# STM32F479 register map
File version: 2.0
CPU: CM4 r0p1, little endian, MPU, FPU, 4 interrupt priority bits
Registers are 32-bit, read-write, reset 0x0 unless marked. A register's access mark holds for its fields unless they carry their own. Offsets are from the block's base; [hi:lo] are bit positions; {n}, {i} and the like mark numbered series.

## EXTI — External interrupt/event controller
Base 0x40013C00
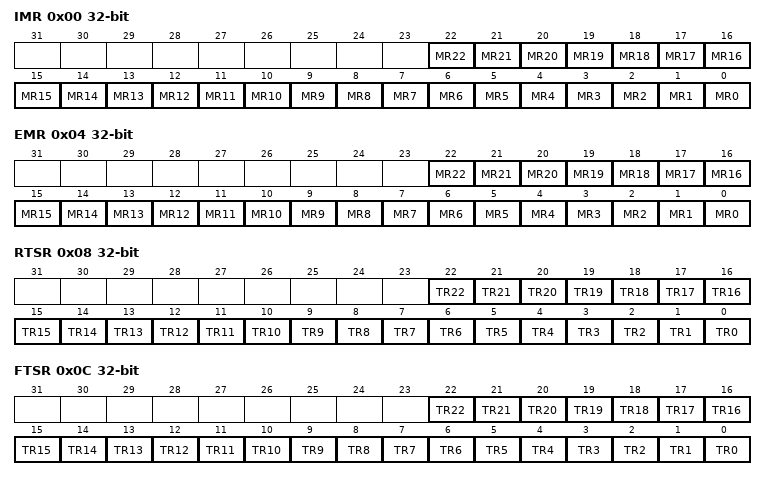
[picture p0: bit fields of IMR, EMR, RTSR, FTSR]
0x00 IMR — Interrupt mask register (EXTI_IMR)
  [n] MR{n} (n=0..22) — Interrupt Mask on line {n}
0x04 EMR — Event mask register (EXTI_EMR)
  [n] MR{n} (n=0..22) — Event Mask on line {n}
0x08 RTSR — Rising Trigger selection register (EXTI_RTSR)
  [n] TR{n} (n=0..22) — Rising trigger event configuration of line {n}
0x0C FTSR — Falling Trigger selection register (EXTI_FTSR)
  [n] TR{n} (n=0..22) — Falling trigger event configuration of line {n}
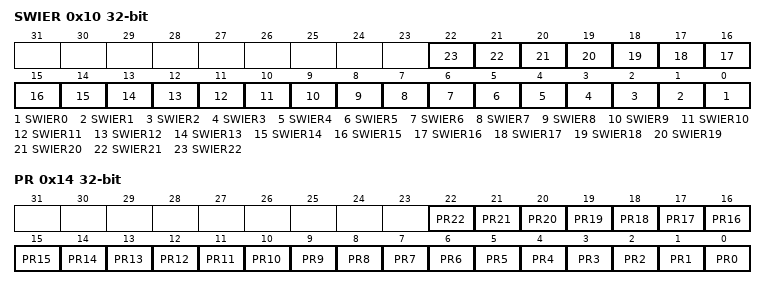
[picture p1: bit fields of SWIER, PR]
0x10 SWIER — Software interrupt event register (EXTI_SWIER)
  [n] SWIER{n} (n=0..22) — Software Interrupt on line {n}
0x14 PR — Pending register (EXTI_PR)
  [n] PR{n} (n=0..22) — Pending bit {n}

## Ethernet_DMA — Ethernet: DMA controller operation
Base 0x40029000
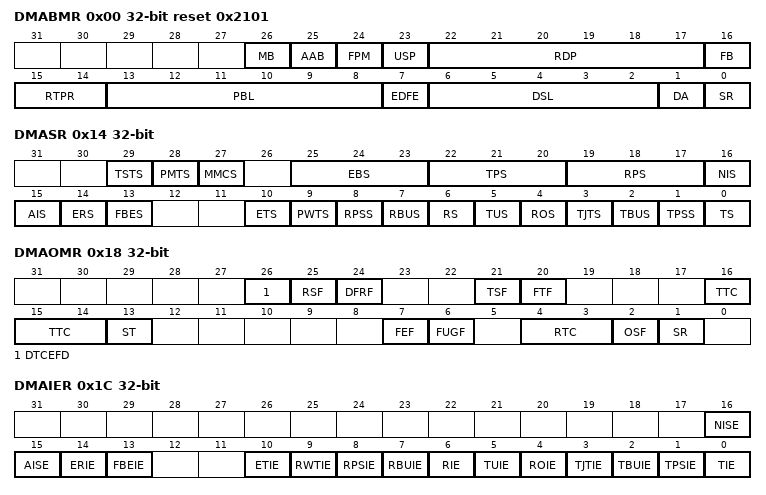
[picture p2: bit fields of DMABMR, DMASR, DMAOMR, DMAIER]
0x00 DMABMR reset 0x2101 — Ethernet DMA bus mode register
  [26] MB, [25] AAB, [24] FPM, [23] USP, [22:17] RDP, [16] FB, [15:14] RTPR, [13:8] PBL, [7] EDFE, [6:2] DSL, [1] DA, [0] SR
0x04 DMATPDR — Ethernet DMA transmit poll demand register
  [31:0] TPD
0x08 DMARPDR — EHERNET DMA receive poll demand register
  [31:0] RPD
0x0C DMARDLAR — Ethernet DMA receive descriptor list address register
  [31:0] SRL
0x10 DMATDLAR — Ethernet DMA transmit descriptor list address register
  [31:0] STL
0x14 DMASR access per field — Ethernet DMA status register
  [29] TSTS ro, [28] PMTS ro, [27] MMCS ro, [25:23] EBS ro, [22:20] TPS ro, [19:17] RPS ro, [16] NIS rw, [15] AIS rw, [14] ERS rw, [13] FBES rw, [10] ETS rw, [9] PWTS rw, [8] RPSS rw, [7] RBUS rw, [6] RS rw, [5] TUS rw, [4] ROS rw, [3] TJTS rw, [2] TBUS rw, [1] TPSS rw, [0] TS rw
0x18 DMAOMR — Ethernet DMA operation mode register
  [26] DTCEFD, [25] RSF, [24] DFRF, [21] TSF, [20] FTF, [16:14] TTC, [13] ST, [7] FEF, [6] FUGF, [4:3] RTC, [2] OSF, [1] SR
0x1C DMAIER — Ethernet DMA interrupt enable register
  [16] NISE, [15] AISE, [14] ERIE, [13] FBEIE, [10] ETIE, [9] RWTIE, [8] RPSIE, [7] RBUIE, [6] RIE, [5] TUIE, [4] ROIE, [3] TJTIE, [2] TBUIE, [1] TPSIE, [0] TIE
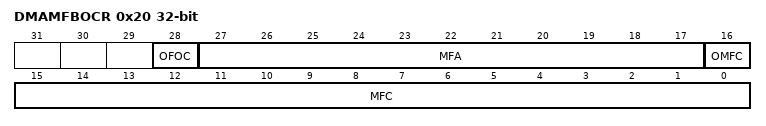
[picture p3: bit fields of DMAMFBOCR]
0x20 DMAMFBOCR — Ethernet DMA missed frame and buffer overflow counter register
  [28] OFOC, [27:17] MFA, [16] OMFC, [15:0] MFC
0x24 DMARSWTR — Ethernet DMA receive status watchdog timer register
  [7:0] RSWTC
0x48 DMACHTDR ro — Ethernet DMA current host transmit descriptor register
  [31:0] HTDAP
0x4C DMACHRDR ro — Ethernet DMA current host receive descriptor register
  [31:0] HRDAP
0x50 DMACHTBAR ro — Ethernet DMA current host transmit buffer address register
  [31:0] HTBAP
0x54 DMACHRBAR ro — Ethernet DMA current host receive buffer address register
  [31:0] HRBAP

## Ethernet_MAC — Ethernet: media access control (MAC)
Base 0x40028000
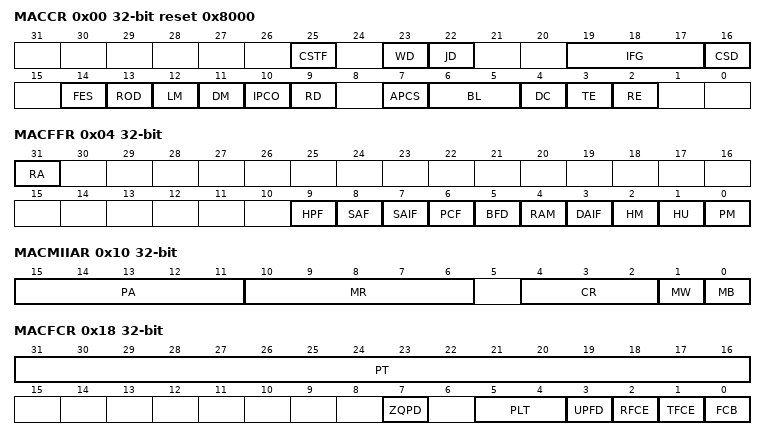
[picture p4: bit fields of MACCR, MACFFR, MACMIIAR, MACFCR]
0x00 MACCR reset 0x8000 — Ethernet MAC configuration register
  [25] CSTF, [23] WD, [22] JD, [19:17] IFG, [16] CSD, [14] FES, [13] ROD, [12] LM, [11] DM, [10] IPCO, [9] RD, [7] APCS, [6:5] BL, [4] DC, [3] TE, [2] RE
0x04 MACFFR — Ethernet MAC frame filter register
  [31] RA, [9] HPF, [8] SAF, [7] SAIF, [6] PCF, [5] BFD, [4] RAM, [3] DAIF, [2] HM, [1] HU, [0] PM
0x08 MACHTHR — Ethernet MAC hash table high register
  [31:0] HTH
0x0C MACHTLR — Ethernet MAC hash table low register
  [31:0] HTL
0x10 MACMIIAR — Ethernet MAC MII address register
  [15:11] PA, [10:6] MR, [4:2] CR, [1] MW, [0] MB
0x14 MACMIIDR — Ethernet MAC MII data register
  [15:0] TD
0x18 MACFCR — Ethernet MAC flow control register
  [31:16] PT, [7] ZQPD, [5:4] PLT, [3] UPFD, [2] RFCE, [1] TFCE, [0] FCB
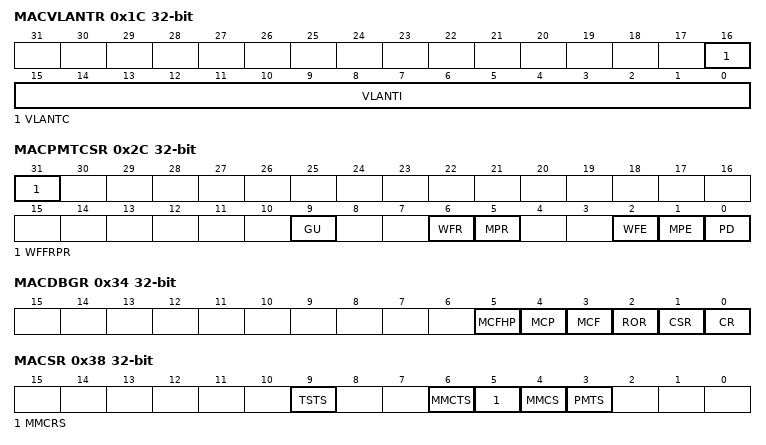
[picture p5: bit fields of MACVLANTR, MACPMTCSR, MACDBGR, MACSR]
0x1C MACVLANTR — Ethernet MAC VLAN tag register
  [16] VLANTC, [15:0] VLANTI
0x2C MACPMTCSR — Ethernet MAC PMT control and status register
  [31] WFFRPR, [9] GU, [6] WFR, [5] MPR, [2] WFE, [1] MPE, [0] PD
0x34 MACDBGR ro — Ethernet MAC debug register
  [5] MCFHP, [4] MCP, [3] MCF, [2] ROR, [1] CSR, [0] CR
0x38 MACSR access per field — Ethernet MAC interrupt status register
  [9] TSTS rw, [6] MMCTS ro, [5] MMCRS ro, [4] MMCS ro, [3] PMTS ro
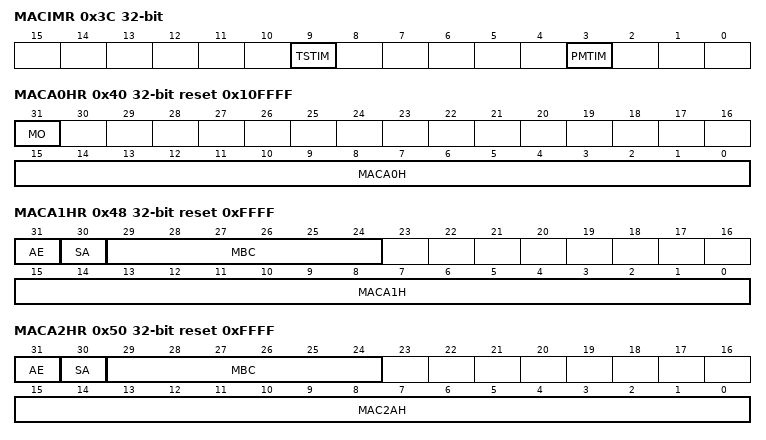
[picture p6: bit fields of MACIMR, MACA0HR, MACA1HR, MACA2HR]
0x3C MACIMR — Ethernet MAC interrupt mask register
  [9] TSTIM, [3] PMTIM
0x40 MACA0HR access per field reset 0x10FFFF — Ethernet MAC address 0 high register
  [31] MO ro — Always 1
  [15:0] MACA0H rw — MAC address0 high
0x44 MACA0LR reset 0xFFFFFFFF — Ethernet MAC address 0 low register
  [31:0] MACA0L — 0
0x48 MACA1HR reset 0xFFFF — Ethernet MAC address 1 high register
  [31] AE, [30] SA, [29:24] MBC, [15:0] MACA1H
0x4C MACA1LR reset 0xFFFFFFFF — Ethernet MAC address1 low register
0x50 MACA2HR reset 0xFFFF — Ethernet MAC address 2 high register
  [31] AE, [30] SA, [29:24] MBC, [15:0] MAC2AH
0x54 MACA2LR reset 0xFFFFFFFF — Ethernet MAC address 2 low register
  [30:0] MACA2L
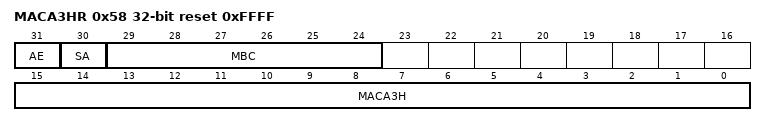
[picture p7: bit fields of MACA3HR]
0x58 MACA3HR reset 0xFFFF — Ethernet MAC address 3 high register
  [31] AE, [30] SA, [29:24] MBC, [15:0] MACA3H
0x5C MACA3LR reset 0xFFFFFFFF — Ethernet MAC address 3 low register
  [31:0] MBCA3L
